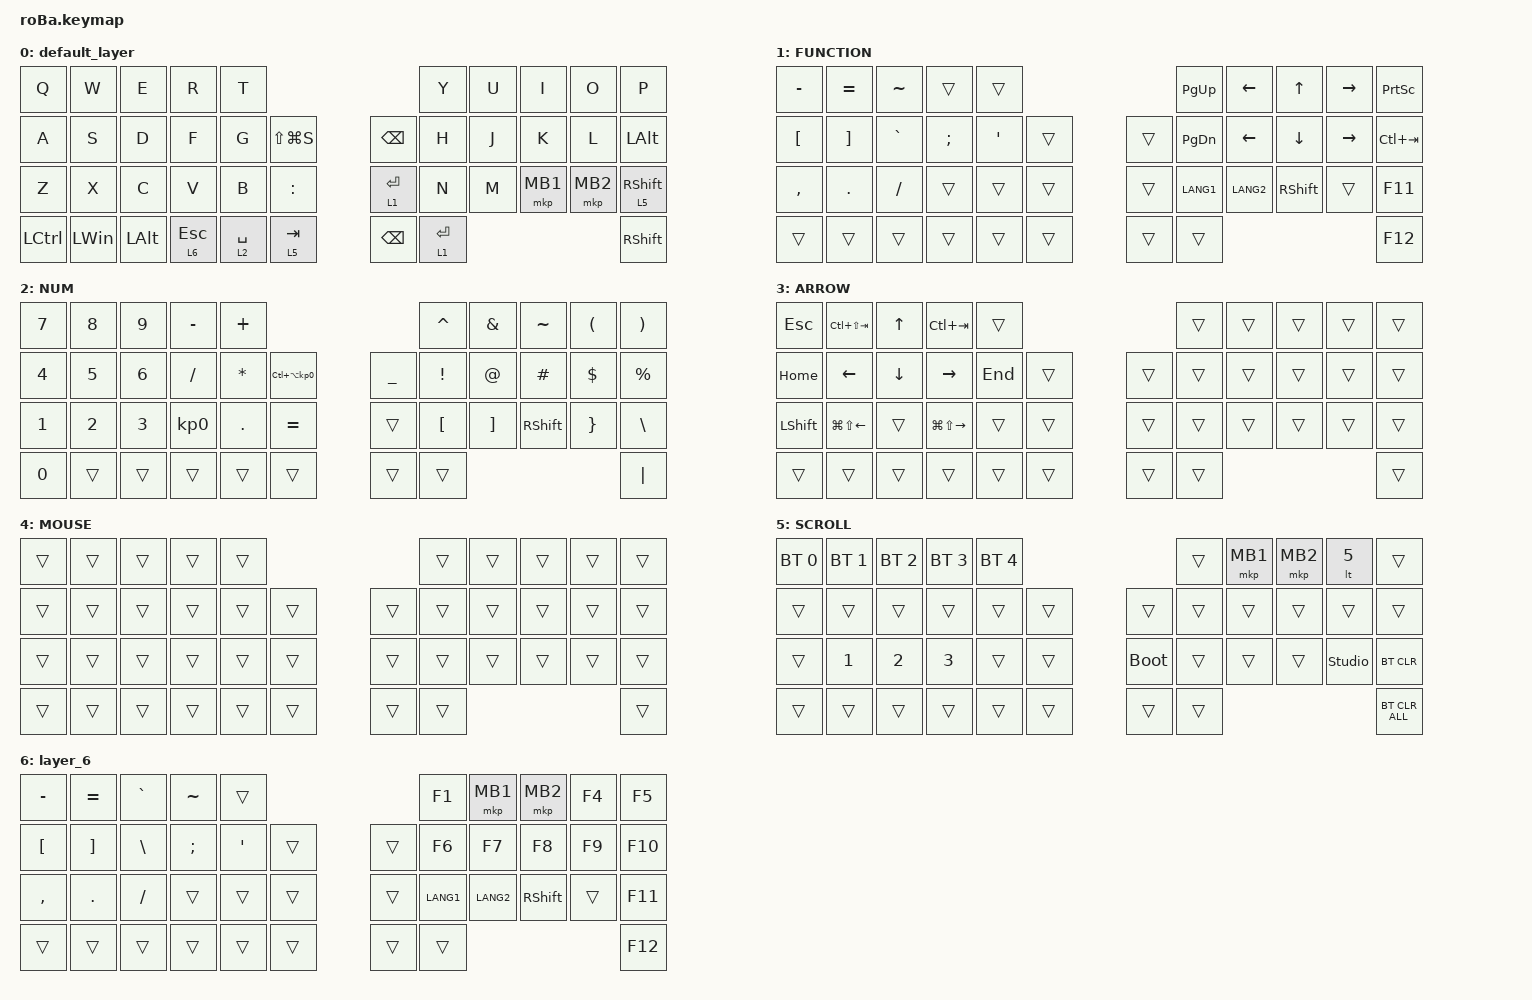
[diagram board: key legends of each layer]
#include <dt-bindings/zmk/mouse.h>
#include <behaviors.dtsi>
#include <dt-bindings/zmk/bt.h>
#include <dt-bindings/zmk/keys.h>

#define MOUSE 4
#define SCROLL 5
#define NUM 6

&mt {
    flavor = "balanced";
    quick-tap-ms = <0>;
};

/ {
    combos {
        compatible = "zmk,combos";

        tab {
            bindings = <&kp TAB>;
            key-positions = <11 12>;
        };

        shift_tab {
            bindings = <&kp LS(TAB)>;
            key-positions = <12 13>;
        };

        muhennkann {
            bindings = <&to_layer_0 INT_MUHENKAN>;
            key-positions = <11 10>;
        };

        double_quotation {
            bindings = <&kp DOUBLE_QUOTES>;
            key-positions = <20 21>;
        };

        eq {
            bindings = <&kp EQUAL>;
            key-positions = <24 25>;
        };
    };

    macros {
        to_layer_0: to_layer_0 {
            compatible = "zmk,behavior-macro-one-param";
            #binding-cells = <1>;
            bindings = <&to 0 &macro_param_1to1 &kp MACRO_PLACEHOLDER>;
            label = "TO_LAYER_0";
        };
    };

    behaviors {
        lt_to_layer_0: lt_to_layer_0 {
            compatible = "zmk,behavior-hold-tap";
            label = "LAYER_TAP_TO_0";
            bindings = <&mo>, <&to_layer_0>;

            #binding-cells = <2>;
            tapping-term-ms = <200>;
        };
    };

    keymap {
        compatible = "zmk,keymap";

        default_layer {
            bindings = <
            &kp Q             &kp W         &kp E         &kp R                        &kp T                                                          &kp Y        &kp U  &kp I    &kp O    &kp P
            &kp A             &kp S         &kp D         &kp F                        &kp G        &kp LS(LG(S))                      &kp BACKSPACE  &kp H        &kp J  &kp K      &kp L    &kp LALT
            &kp Z             &kp X         &kp C         &kp V                        &kp B        &kp COLON                          &lt 1 ENTER    &kp N        &kp M  &mkp MB1  &mkp MB2  &lt_to_layer_0 5 RIGHT_SHIFT
            &kp LCTRL         &kp LEFT_WIN  &kp LEFT_ALT  &lt_to_layer_0 6 ESC         &lt 2 SPACE  &lt_to_layer_0 5 TAB               &kp BACKSPACE  &lt 1 ENTER                             &kp RIGHT_SHIFT
                        >;
            sensor-bindings = <&inc_dec_kp C_VOL_DN C_VOL_UP>;
        };

        FUNCTION {
            bindings = <
&kp MINUS  &kp EQUAL  &kp TILDE  &trans  &trans                    &kp PG_UP    &kp LEFT_ARROW               &kp UP_ARROW  &kp RIGHT_ARROW  &kp PSCRN
&kp LBKT &kp RBKT  &kp GRAVE  &kp SEMI  &kp SQT  &trans    &trans  &kp PG_DN    &kp LEFT_ARROW               &kp DOWN_ARROW  &kp RIGHT_ARROW  &kp LC(TAB)
&kp COMMA  &kp DOT   &kp SLASH  &trans  &trans  &trans    &trans  &kp LANG1  &kp LANG2  &kp RIGHT_SHIFT  &trans  &kp F11
&trans  &trans  &trans  &trans  &trans  &trans    &trans  &trans                                         &kp F12
            >;
        };

        NUM {
            bindings = <
&kp NUMBER_7  &kp NUMBER_8  &kp NUMBER_9 &kp MINUS      &kp PLUS                                                 &kp CARET         &kp AMPERSAND      &kp TILDE       &kp LEFT_PARENTHESIS  &kp RIGHT_PARENTHESIS
&kp NUMBER_4  &kp NUMBER_5  &kp NUMBER_6  &kp SLASH     &kp ASTERISK  &kp LC(LA(KP_NUMBER_0))    &kp UNDERSCORE  &kp EXCLAMATION   &kp AT_SIGN        &kp HASH        &kp DOLLAR            &kp PERCENT
&kp NUMBER_1  &kp NUMBER_2  &kp NUMBER_3  &kp KP_NUMBER_0  &kp PERIOD    &kp EQUAL                  &trans          &kp LEFT_BRACKET  &kp RIGHT_BRACKET  &kp RIGHT_SHIFT  &kp RIGHT_BRACE       &kp BACKSLASH
&kp NUMBER_0                      &trans           &trans           &trans           &trans        &trans                     &trans          &trans                                                                     &kp PIPE
            >;
        };

        ARROW {
            bindings = <
&kp ESCAPE      &kp LC(LS(TAB))         &kp UP_ARROW    &kp LC(TAB)              &trans                     &trans  &trans  &trans  &trans  &trans
&kp HOME        &kp LEFT_ARROW          &kp DOWN_ARROW  &kp RIGHT_ARROW          &kp END  &trans    &trans  &trans  &trans  &trans  &trans  &trans
&kp LEFT_SHIFT  &kp LG(LS(LEFT_ARROW))  &trans          &kp LG(LS(RIGHT_ARROW))  &trans   &trans    &trans  &trans  &trans  &trans  &trans  &trans
&trans          &trans                  &trans          &trans                   &trans   &trans    &trans  &trans                          &trans
            >;

            sensor-bindings = <&inc_dec_kp LC(PAGE_UP) LC(PAGE_DOWN)>;
        };

        MOUSE {
            bindings = <
&trans  &trans  &trans  &trans  &trans                    &trans    &trans    &trans    &trans   &trans
&trans  &trans  &trans  &trans  &trans  &trans    &trans  &trans    &trans    &trans    &trans    &trans
&trans  &trans  &trans  &trans  &trans  &trans    &trans  &trans    &trans    &trans    &trans    &trans
&trans  &trans  &trans  &trans  &trans  &trans    &trans  &trans                                &trans
            >;
        };

        SCROLL {
                    bindings = <
        &bt BT_SEL 0  &bt BT_SEL 1        &bt BT_SEL 2        &bt BT_SEL 3        &bt BT_SEL 4                         &trans  &mkp MB1  &mkp MB2  &lt 5  &trans
        &trans  &trans        &trans        &trans        &trans  &trans    &trans       &trans        &trans        &trans        &trans        &trans
        &trans  &kp NUMBER_1  &kp NUMBER_2  &kp NUMBER_3  &trans  &trans    &bootloader  &trans        &trans        &trans        &studio_unlock        &bt BT_CLR
        &trans  &trans        &trans        &trans        &trans  &trans    &trans       &trans                                                  &bt BT_CLR_ALL
                                   >;
        };

        layer_6 {
            bindings = <
                       &kp MINUS  &kp EQUAL  &kp GRAVE  &kp TILDE  &trans                    &kp F1    &mkp MB1               &mkp MB2  &kp F4  &kp F5
                       &kp LBKT &kp RBKT  &kp BACKSLASH  &kp SEMI  &kp SQT  &trans    &trans  &kp F6    &kp F7               &kp F8  &kp F9  &kp F10
                       &kp COMMA  &kp DOT   &kp SLASH  &trans  &trans  &trans    &trans  &kp LANG1  &kp LANG2  &kp RIGHT_SHIFT  &trans  &kp F11
                       &trans  &trans  &trans  &trans  &trans  &trans    &trans  &trans                                         &kp F12
            >;
        };
    };
};
